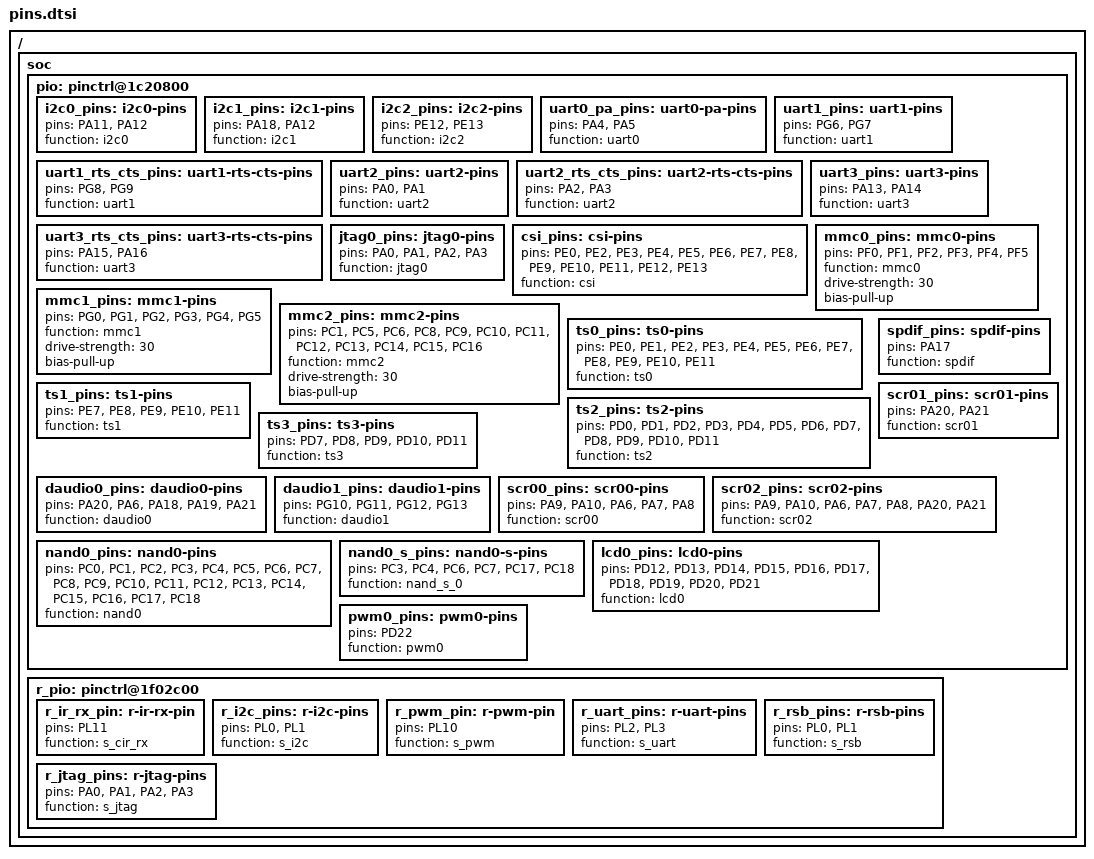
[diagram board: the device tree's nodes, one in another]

/ {
	soc {
		pio: pinctrl@1c20800 {
			/* aosp:
				twi0@0 {
					linux,phandle = <0xa4>;
					phandle = <0xa4>;
					allwinner,pins = "PA11\0PA12";
					allwinner,function = "twi0";
					allwinner,pname = "twi0_scl\0twi0_sda";
					allwinner,muxsel = <0x02>;
					allwinner,pull = <0xffffffff>;
					allwinner,drive = <0xffffffff>;
					allwinner,data = <0xffffffff>;
				};	
			*/
			i2c0_pins: i2c0-pins { /* GOOD */
				pins = "PA11", "PA12";
				function = "i2c0";
			};

			/* 
				twi1@0 {
					linux,phandle = <0xa6>;
					phandle = <0xa6>;
					allwinner,pins = "PA18\0PA19";
					allwinner,function = "twi1";
					allwinner,pname = "twi1_scl\0twi1_sda";
					allwinner,muxsel = <0x03>;
					allwinner,pull = <0xffffffff>;
					allwinner,drive = <0xffffffff>;
					allwinner,data = <0xffffffff>;
				};
			*/
			i2c1_pins: i2c1-pins {  /* GOOD */
				pins = "PA18", "PA12";
				function = "i2c1";
			};

			/*
				twi2@1 {
					linux,phandle = <0xa9>;
					phandle = <0xa9>;
					allwinner,pins = "PE12\0PE13";
					allwinner,function = "twi2";
					allwinner,pname = "twi2_scl\0twi2_sda";
					allwinner,muxsel = <0x07>;
					allwinner,pull = <0xffffffff>;
					allwinner,drive = <0xffffffff>;
					allwinner,data = <0xffffffff>;
				};	
			*/
			i2c2_pins: i2c2-pins {  /* GOOD */
				pins = "PE12", "PE13";
				function = "i2c2";
			};


			/*
				aosp:
				uart0@0 {
					linux,phandle = <0xaa>;
					phandle = <0xaa>;
					allwinner,pins = "PA4\0PA5";
					allwinner,function = "uart0";
					allwinner,pname = "uart0_tx\0uart0_rx";
					allwinner,muxsel = <0x02>;
					allwinner,pull = <0x01>;
					allwinner,drive = <0xffffffff>;
					allwinner,data = <0xffffffff>;
				};

				uart_para@0 {
					linux,phandle = <0xa2>;
					phandle = <0xa2>;
					allwinner,pins = "PA4\0PA5";
					allwinner,function = "uart_para";
					allwinner,pname = "uart_debug_tx\0uart_debug_rx";
					allwinner,muxsel = <0x02>;
					allwinner,pull = <0x01>;
					allwinner,drive = <0xffffffff>;
					allwinner,data = <0xffffffff>;
				};
			*/
			uart0_pa_pins: uart0-pa-pins {  /* GOOD */
				pins = "PA4", "PA5";
				function = "uart0";
			};
			

			/*
				aosp:
				uart1@0 {
					linux,phandle = <0xac>;
					phandle = <0xac>;
					allwinner,pins = "PG6\0PG7\0PG8\0PG9";
					allwinner,function = "uart1";
					allwinner,pname = "uart1_tx\0uart1_rx\0uart1_rts\0uart1_cts";
					allwinner,muxsel = <0x02>;
					allwinner,pull = <0x01>;
					allwinner,drive = <0xffffffff>;
					allwinner,data = <0xffffffff>;
				};
			*/
			uart1_pins: uart1-pins {
				pins = "PG6", "PG7";
				function = "uart1";
			};

			uart1_rts_cts_pins: uart1-rts-cts-pins {
				pins = "PG8", "PG9";
				function = "uart1";
			};


			/*
				aosp:
				uart2@0 {
					linux,phandle = <0xae>;
					phandle = <0xae>;
					allwinner,pins = "PA0\0PA1\0PA2\0PA3";
					allwinner,function = "uart2";
					allwinner,pname = "uart2_tx\0uart2_rx\0uart2_rts\0uart2_cts";
					allwinner,muxsel = <0x02>;
					allwinner,pull = <0x01>;
					allwinner,drive = <0xffffffff>;
					allwinner,data = <0xffffffff>;
				};
			*/
			uart2_pins: uart2-pins {
				pins = "PA0", "PA1";
				function = "uart2";
			};

			uart2_rts_cts_pins: uart2-rts-cts-pins {
				pins = "PA2", "PA3";
				function = "uart2";
			};

			/*	aosp:
				uart3@0 {
					linux,phandle = <0xb0>;
					phandle = <0xb0>;
					allwinner,pins = "PA13\0PA14\0PA15\0PA16";
					allwinner,function = "uart3";
					allwinner,pname = "uart3_tx\0uart3_rx\0uart3_rts\0uart3_cts";
					allwinner,muxsel = <0x02>;
					allwinner,pull = <0x01>;
					allwinner,drive = <0xffffffff>;
					allwinner,data = <0xffffffff>;
				};
			*/
			uart3_pins: uart3-pins {
				pins = "PA13", "PA14";
				function = "uart3";
			};

			uart3_rts_cts_pins: uart3-rts-cts-pins {
				pins = "PA15", "PA16";
				function = "uart3";
			};

			/*	aosp:
				jtag_para@0 {
					linux,phandle = <0xa3>;
					phandle = <0xa3>;
					allwinner,pins = "PA0\0PA1\0PA2\0PA3";
					allwinner,function = "jtag_para";
					allwinner,pname = "jtag_ms\0jtag_ck\0jtag_do\0jtag_di";
					allwinner,muxsel = <0x03>;
					allwinner,pull = <0xffffffff>;
					allwinner,drive = <0xffffffff>;
					allwinner,data = <0xffffffff>;
				};
			*/
			jtag0_pins: jtag0-pins {
				pins = "PA0", "PA1", "PA2", "PA3";
				function = "jtag0";
			};
			
			/*
				aosp:
				csi0@0 {
					linux,phandle = <0xc4>;
					phandle = <0xc4>;
					allwinner,pins = "PE0\0PE2\0PE3\0PE4\0PE5\0PE6\0PE7\0PE8\0PE9\0PE10\0PE11\0PE12\0PE13";
					allwinner,function = "csi0";
					allwinner,pname = "csi0_pck\0csi0_hsync\0csi0_vsync\0csi0_d0\0csi0_d1\0csi0_d2\0csi0_d3\0csi0_d4\0csi0_d5\0csi0_d6\0csi0_d7\0csi0_sck\0csi0_sda";
					allwinner,muxsel = <0x02>;
					allwinner,pull = <0xffffffff>;
					allwinner,drive = <0xffffffff>;
					allwinner,data = <0xffffffff>;
				};

				csi0_sleep@0 {
					allwinner,pins = "PE0\0PE2\0PE3\0PE4\0PE5\0PE6\0PE7\0PE8\0PE9\0PE10\0PE11\0PE12\0PE13";
					allwinner,pname = "csi0_pck\0csi0_hsync\0csi0_vsync\0csi0_d0\0csi0_d1\0csi0_d2\0csi0_d3\0csi0_d4\0csi0_d5\0csi0_d6\0csi0_d7\0csi0_sck\0csi0_sda";
					allwinner,function = "io_disabled";
					allwinner,muxsel = <0x07>;
					allwinner,drive = <0x01>;
					allwinner,pull = <0x00>;
					allwinner,data = <0x00>;
					linux,phandle = <0x6f>;
					phandle = <0x6f>;
				};
			*/
			csi_pins: csi-pins { 
				pins = "PE0", "PE2", "PE3", "PE4", "PE5",
				       "PE6", "PE7", "PE8", "PE9", "PE10",
				       "PE11", "PE12", "PE13";
				function = "csi";
			};
			
			/*
				sdc0@0 {
					linux,phandle = <0xc5>;
					phandle = <0xc5>;
					allwinner,pins = "PF0\0PF1\0PF2\0PF3\0PF4\0PF5";
					allwinner,function = "sdc0";
					allwinner,pname = "sdc0_d1\0sdc0_d0\0sdc0_clk\0sdc0_cmd\0sdc0_d3\0sdc0_d2";
					allwinner,muxsel = <0x02>;
					allwinner,pull = <0x01>;
					allwinner,drive = <0x02>;
					allwinner,data = <0xffffffff>;
				};
			*/
			mmc0_pins: mmc0-pins {
				pins = "PF0", "PF1", "PF2", "PF3",
				       "PF4", "PF5";
				function = "mmc0";
				drive-strength = <30>;
				bias-pull-up;
			};

			/*
				sdc1@0 {
					linux,phandle = <0xc6>;
					phandle = <0xc6>;
					allwinner,pins = "PG0\0PG1\0PG2\0PG3\0PG4\0PG5";
					allwinner,function = "sdc1";
					allwinner,pname = "sdc1_clk\0sdc1_cmd\0sdc1_d0\0sdc1_d1\0sdc1_d2\0sdc1_d3";
					allwinner,muxsel = <0x02>;
					allwinner,pull = <0x01>;
					allwinner,drive = <0x03>;
					allwinner,data = <0xffffffff>;
				};
			*/
			mmc1_pins: mmc1-pins {
				pins = "PG0", "PG1", "PG2", "PG3",
				       "PG4", "PG5";
				function = "mmc1";
				drive-strength = <30>;
				bias-pull-up;
			};

			/*
				sdc2@0 {
					linux,phandle = <0xc7>;
					phandle = <0xc7>;
					allwinner,pins = "PC1\0PC5\0PC6\0PC8\0PC9\0PC10\0PC11\0PC12\0PC13\0PC14\0PC15\0PC16";
					allwinner,function = "sdc2";
					allwinner,pname = "sdc2_ds\0sdc2_clk\0sdc2_cmd\0sdc2_d0\0sdc2_d1\0sdc2_d2\0sdc2_d3\0sdc2_d4\0sdc2_d5\0sdc2_d6\0sdc2_d7\0sdc2_emmc_rst";
					allwinner,muxsel = <0x03>;
					allwinner,pull = <0x01>;
					allwinner,drive = <0x03>;
					allwinner,data = <0xffffffff>;
				};
			*/
			mmc2_pins: mmc2-pins {
				pins = "PC1", "PC5", "PC6", 
				       "PC8", "PC9", "PC10",
				       "PC11", "PC12", "PC13",
				       "PC14", "PC15", "PC16";
				/*pins = "PC5", "PC6", "PC8", 
				       "PC9", "PC10", "PC11",
				       "PC12", "PC13", "PC14",
				       "PC15", "PC16"; */ // << aosp 
				function = "mmc2";
				drive-strength = <30>;
				bias-pull-up;
			};

			/*
				aosp:
				ts0@0 {
					allwinner,pins = "PE0\0PE1\0PE2\0PE3\0PE4\0PE5\0PE6\0PE7\0PE8\0PE9\0PE10\0PE11";
					allwinner,pname = "ts0_clk\0ts0_err\0ts0_sync\0ts0_dvld\0ts0_d0\0ts0_d1\0ts0_d2\0ts0_d3\0ts0_d4\0ts0_d5\0ts0_d6\0ts0_d7";
					allwinner,function = "ts0";
					allwinner,muxsel = <0x03>;
					allwinner,drive = <0x01>;
					allwinner,pull = <0x00>;
					linux,phandle = <0x81>;
					phandle = <0x81>;
				};
			*/
			ts0_pins: ts0-pins { 
				pins = "PE0", "PE1", "PE2", "PE3", "PE4",
				       "PE5", "PE6", "PE7", "PE8", "PE9",
				       "PE10", "PE11";
				function = "ts0";
			};
			

			/*
				ts1@0 {
					allwinner,pins = "PE7\0PE8\0PE9\0PE10\0PE11";
					allwinner,pname = "ts1_clk\0ts1_err\0ts1_sync\0ts1_dvld\0ts1_d0";
					allwinner,function = "ts1";
					allwinner,muxsel = <0x04>;
					allwinner,drive = <0x01>;
					allwinner,pull = <0x00>;
					linux,phandle = <0x82>;
					phandle = <0x82>;
				};
			*/
			ts1_pins: ts1-pins { 
				pins = "PE7", "PE8", "PE9", "PE10", "PE11";
				function = "ts1";
			};

			/*
				ts2@0 {
					allwinner,pins = "PD0\0PD1\0PD2\0PD3\0PD4\0PD5\0PD6\0PD7\0PD8\0PD9\0PD10\0PD11";
					allwinner,pname = "ts2_clk\0ts2_err\0ts2_sync\0ts2_dvld\0ts2_d0\0ts2_d1\0ts2_d2\0ts2_d3\0ts2_d4\0ts2_d5\0ts2_d6\0ts2_d7";
					allwinner,function = "ts2";
					allwinner,muxsel = <0x04>;
					allwinner,drive = <0x01>;
					allwinner,pull = <0x00>;
					linux,phandle = <0x83>;
					phandle = <0x83>;
				};
			*/
			ts2_pins: ts2-pins { 
				pins = "PD0", "PD1", "PD2", "PD3", "PD4", "PD5", "PD6", "PD7", "PD8", "PD9", "PD10", "PD11";
				function = "ts2";
			};

			/*
				ts3@0 {
					allwinner,pins = "PD7\0PD8\0PD9\0PD10\0PD11";
					allwinner,pname = "ts3_clk\0ts3_err\0ts3_sync\0ts3_dvld\0ts3_d0";
					allwinner,function = "ts3";
					allwinner,muxsel = <0x05>;
					allwinner,drive = <0x01>;
					allwinner,pull = <0x00>;
					linux,phandle = <0x84>;
					phandle = <0x84>;
				};
			*/
			ts3_pins: ts3-pins { 
				pins = "PD7", "PD8", "PD9", "PD10", "PD11";
				function = "ts3";
			};


			/*
				aosp:
				daudio0@0 {
					allwinner,pins = "PA20\0PA6\0PA18\0PA19\0PA21";
					allwinner,function = "pcm0";
					allwinner,muxsel = <0x03>;
					allwinner,drive = <0x01>;
					allwinner,pull = <0x00>;
					linux,phandle = <0x3c>;
					phandle = <0x3c>;
				};
			*/
			daudio0_pins: daudio0-pins {
				pins = "PA20", "PA6", "PA18", "PA19", "PA21";
				function = "daudio0"; /*???*/
			};

			/*
				daudio1@0 {
					allwinner,pins = "PG10\0PG11\0PG12\0PG13";
					allwinner,function = "pcm1";
					allwinner,muxsel = <0x02>;
					allwinner,drive = <0x01>;
					allwinner,pull = <0x00>;
					linux,phandle = <0x3e>;
					phandle = <0x3e>;
				};
			*/
			daudio1_pins: daudio1-pins { 
				pins = "PG10", "PG11", "PG12", "PG13";
				function = "daudio1"; /*???*/
			};

			/*
				spdif@0 {
					allwinner,pins = "PA17";
					allwinner,function = "spdif0";
					allwinner,muxsel = <0x02>;
					allwinner,drive = <0x01>;
					allwinner,pull = <0x00>;
					linux,phandle = <0x43>;
					phandle = <0x43>;
				};
			*/
			spdif_pins: spdif-pins { 
				pins = "PA17";
				function = "spdif"; /*???*/
			};

			/*
				scr0@0 {
					allwinner,pins = "PA9\0PA10\0PA6\0PA7\0PA8";
					allwinner,pname = "scr0_rst\0scr0_det\0scr0_vccen\0scr0_sck\0scr0_sda";
					allwinner,function = "sim0";
					allwinner,muxsel = <0x02>;
					allwinner,drive = <0x01>;
					allwinner,pull = <0x01>;
					linux,phandle = <0x75>;
					phandle = <0x75>;
				};
			*/
			scr00_pins: scr00-pins { 
				pins = "PA9", "PA10", "PA6", "PA7", "PA8";
				function = "scr00"; /*???*/
			};

			/*
				scr0@1 {
					allwinner,pins = "PA20\0PA21";
					allwinner,pname = "scr0_vppen\0scr0_vppp";
					allwinner,function = "sim0";
					allwinner,muxsel = <0x03>;
					allwinner,drive = <0x01>;
					allwinner,pull = <0x01>;
					linux,phandle = <0x76>;
					phandle = <0x76>;
				};
			*/
			scr01_pins: scr01-pins { 
				pins = "PA20", "PA21";
				function = "scr01"; /*???*/
			};

			/*
				scr0@2 {
					allwinner,pins = "PA9\0PA10\0PA6\0PA7\0PA8\0PA20\0PA21";
					allwinner,function = "io_disabled";
					allwinner,muxsel = <0x07>;
					allwinner,drive = <0x01>;
					allwinner,pull = <0x00>;
					linux,phandle = <0x77>;
					phandle = <0x77>;
				};
			*/
			scr02_pins: scr02-pins { 
				pins = "PA9", "PA10", "PA6", "PA7", "PA8", "PA20", "PA21";
				function = "scr02"; /*???*/
			};

			/*
				nand0@2 {
					allwinner,pins = "PC0\0PC1\0PC2\0PC3\0PC4\0PC5\0PC6\0PC7\0PC8\0PC9\0PC10\0PC11\0PC12\0PC13\0PC14\0PC15\0PC16\0PC17\0PC18";
					allwinner,function = "io_disabled";
					allwinner,muxsel = <0x07>;
					allwinner,drive = <0x01>;
					allwinner,pull = <0x00>;
					linux,phandle = <0x7f>;
					phandle = <0x7f>;
				};

				nand0@1 {
					linux,phandle = <0xbd>;
					phandle = <0xbd>;
					allwinner,pins = "PC3\0PC4\0PC6\0PC7\0PC17\0PC18";
					allwinner,function = "nand0";
					allwinner,pname = "nand0_ce1\0nand0_ce0\0nand0_rb0\0nand0_rb1\0nand0_ce2\0nand0_ce3";
					allwinner,muxsel = <0x02>;
					allwinner,pull = <0x01>;
					allwinner,drive = <0x01>;
					allwinner,data = <0xffffffff>;
				};
			*/
			nand0_pins: nand0-pins { 
				pins = "PC0", "PC1", "PC2", "PC3", "PC4", "PC5", "PC6", "PC7", "PC8", "PC9", "PC10", "PC11", "PC12", "PC13", "PC14", "PC15", "PC16", "PC17", "PC18";
				function = "nand0"; /*???*/
			};

			nand0_s_pins: nand0-s-pins {  /*???*/
				pins = "PC3", "PC4", "PC6", "PC7", "PC17", "PC18";
				function = "nand_s_0"; /*???*/
			};

			/*
				lcd0@0 {
					linux,phandle = <0xbe>;
					phandle = <0xbe>;
					allwinner,pins = "PD12\0PD13\0PD14\0PD15\0PD16\0PD17\0PD18\0PD19\0PD20\0PD21";
					allwinner,function = "lcd0";
					allwinner,pname = "lcdd0\0lcdd1\0lcdd2\0lcdd3\0lcdd4\0lcdd5\0lcdd6\0lcdd7\0lcdd8\0lcdd9";
					allwinner,muxsel = <0x03>;
					allwinner,pull = <0x00>;
					allwinner,drive = <0xffffffff>;
					allwinner,data = <0xffffffff>;
				};
			*/
			lcd0_pins: lcd0-pins { 
				pins = "PD12", "PD13", "PD14", "PD15", "PD16", "PD17", "PD18", "PD19", "PD20", "PD21";
				function = "lcd0";
			};

			/*
				pwm0@0 {
					linux,phandle = <0xc0>;
					phandle = <0xc0>;
					allwinner,pins = "PD22";
					allwinner,function = "pwm0";
					allwinner,pname = "pwm_positive";
					allwinner,muxsel = <0x02>;
					allwinner,pull = <0x00>;
					allwinner,drive = <0xffffffff>;
					allwinner,data = <0xffffffff>;
				};
			*/
			pwm0_pins: pwm0-pins { 
				pins = "PD22";
				function = "pwm0";
			};
		};

		r_pio: pinctrl@1f02c00 {
			/*
				s_cir0@0 {
					linux,phandle = <0xc8>;
					phandle = <0xc8>;
					allwinner,pins = "PL11";
					allwinner,function = "s_cir0";
					allwinner,pname = "ir_rx";
					allwinner,muxsel = <0x02>;
					allwinner,pull = <0x01>;
					allwinner,drive = <0xffffffff>;
					allwinner,data = <0xffffffff>;
				};
			*/
			r_ir_rx_pin: r-ir-rx-pin {
				pins = "PL11";
				function = "s_cir_rx";
			};
			
			/*
				s_twi0@0 {
					allwinner,pins = "PL0\0PL1";
					allwinner,function = "s_twi0";
					allwinner,muxsel = <0x02>;
					allwinner,drive = <0x02>;
					allwinner,pull = <0x01>;
					linux,phandle = <0x13>;
					phandle = <0x13>;
				};
			*/
			r_i2c_pins: r-i2c-pins {
				pins = "PL0", "PL1";
				function = "s_i2c";
			};
			
			/*
				pwm16@0 {
					linux,phandle = <0xc2>;
					phandle = <0xc2>;
					allwinner,pins = "PL10";
					allwinner,function = "pwm16";
					allwinner,pname = "pwm_positive";
					allwinner,muxsel = <0x02>;
					allwinner,pull = <0x00>;
					allwinner,drive = <0xffffffff>;
					allwinner,data = <0xffffffff>;
				};
			*/
			r_pwm_pin: r-pwm-pin {
				pins = "PL10";
				function = "s_pwm";
			};
		
			/*
				s_uart0@0 {
					linux,phandle = <0xc9>;
					phandle = <0xc9>;
					allwinner,pins = "PL2\0PL3";
					allwinner,function = "s_uart0";
					allwinner,pname = "s_uart0_tx\0s_uart0_rx";
					allwinner,muxsel = <0x02>;
					allwinner,pull = <0xffffffff>;
					allwinner,drive = <0xffffffff>;
					allwinner,data = <0xffffffff>;
				};
			*/
			r_uart_pins: r-uart-pins {
				pins = "PL2", "PL3";
				function = "s_uart";
			};
			
			/*
				aosp:
				s_rsb0@0 {
					linux,phandle = <0xca>;
					phandle = <0xca>;
					allwinner,pins = "PL0\0PL1";
					allwinner,function = "s_rsb0";
					allwinner,pname = "s_rsb0_sck\0s_rsb0_sda";
					allwinner,muxsel = <0x02>;
					allwinner,pull = <0x01>;
					allwinner,drive = <0x02>;
					allwinner,data = <0xffffffff>;
				};
			*/
			r_rsb_pins: r-rsb-pins {  /* ADDED EXT experimentally */
				pins = "PL0", "PL1";
				function = "s_rsb";
			};

			/*	aosp:
				jtag_para@0 {
					linux,phandle = <0xa3>;
					phandle = <0xa3>;
					allwinner,pins = "PA0\0PA1\0PA2\0PA3";
					allwinner,function = "jtag_para";
					allwinner,pname = "jtag_ms\0jtag_ck\0jtag_do\0jtag_di";
					allwinner,muxsel = <0x03>;
					allwinner,pull = <0xffffffff>;
					allwinner,drive = <0xffffffff>;
					allwinner,data = <0xffffffff>;
				};
			*/
			r_jtag_pins: r-jtag-pins {
				pins = "PA0", "PA1", "PA2", "PA3";
				function = "s_jtag";
			};
		};
	};
};

